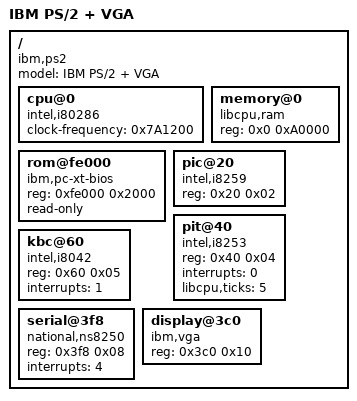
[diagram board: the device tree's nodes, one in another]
/dts-v1/;

/* IBM PS/2-class machine with a VGA adapter. The VGA is a superset of the EGA register model
   (0x3C0-0x3CF + colour CRTC at 0x3D4/0x3D5) with the addition of the RAMDAC colour palette at
   0x3C7-0x3C9; mode-13h linear graphics live at 0xA0000 and the colour-text page at 0xB8000.
   Only the display node differs from the other variants. */

/ {
    model = "IBM PS/2 + VGA";
    compatible = "ibm,ps2", "ibm,pc-at";
    #address-cells = <1>;
    #size-cells = <1>;

    cpu@0 {
        device_type = "cpu";
        compatible = "intel,i80286";
        clock-frequency = <0x7A1200>;   /* 8 MHz */
    };

    memory@0 {
        device_type = "memory";
        compatible = "libcpu,ram";
        reg = <0x0 0xA0000>;
    };

    rom@fe000 {
        compatible = "ibm,pc-xt-bios";
        reg = <0xfe000 0x2000>;
        read-only;
    };

    pic@20 {
        compatible = "intel,i8259";
        reg = <0x20 0x02>;
    };

    pit@40 {
        compatible = "intel,i8253";
        reg = <0x40 0x04>;
        interrupts = <0>;
        libcpu,ticks = <5>;
    };

    kbc@60 {
        compatible = "intel,i8042";
        reg = <0x60 0x05>;              /* 8042 KBC: data 0x60, command/status 0x64 */
        interrupts = <1>;               /* keyboard -> IRQ1 */
    };

    serial@3f8 {
        compatible = "national,ns8250";
        reg = <0x3f8 0x08>;
        interrupts = <4>;
    };

    display@3c0 {
        compatible = "ibm,vga";
        reg = <0x3c0 0x10>;             /* attribute/sequencer/DAC/graphics + CRTC at 0x3d4 (fb A0000/B8000) */
    };
};
